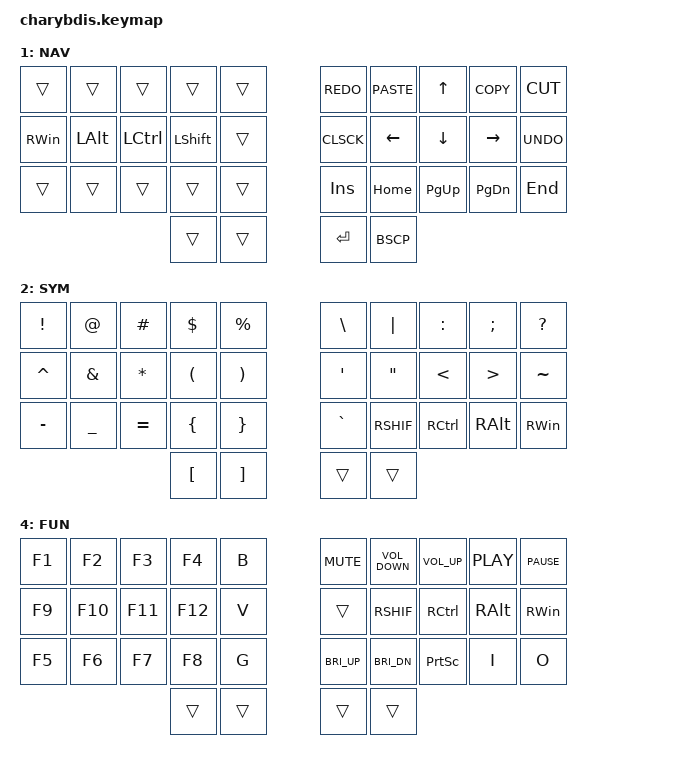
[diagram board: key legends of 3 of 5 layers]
#include <behaviors/mouse_keys.dtsi>
#include <behaviors.dtsi>
#include <dt-bindings/zmk/bt.h>
#include <dt-bindings/zmk/keys.h>
#include <dt-bindings/zmk/mouse.h>
#include <dt-bindings/zmk/outputs.h>

#define U_TAPPING_TERM 200

/ {
    chosen { zmk,matrix_transform = &default_transform; };
};

/ {
    combos {
        compatible = "zmk,combos";

        Combo_Num {
            bindings = <&mo NUM>;
            key-positions = <32 33>;  # Las posiciones de las dos teclas que quieres usar
        };
        Combo_Nav {
            bindings = <&mo NAV>;
            key-positions = <31 34>;  # Las posiciones de las dos teclas que quieres usar
        };
    };

    behaviors {
        u_mt: u_mt {
            compatible = "zmk,behavior-hold-tap";
            label = "u_mt";
            #binding-cells = <2>;
            tapping_term_ms = <U_TAPPING_TERM>;
            flavor = "tap-preferred";
            bindings = <&kp>, <&kp>;
        };

        u_lt: u_lt {
            compatible = "zmk,behavior-hold-tap";
            label = "u_lt";
            #binding-cells = <2>;
            tapping_term_ms = <U_TAPPING_TERM>;
            flavor = "tap-preferred";
            bindings = <&mo>, <&kp>;
        };

        Shift_Enter: Shift_Enter {
            compatible = "zmk,behavior-hold-tap";
            label = "SHIFT_ENTER";
            bindings = <&kp>, <&kp>;

            #binding-cells = <2>;
            hold-trigger-key-positions = <40>;
            tapping-term-ms = <100>;
        };
    };

    keymap {
        compatible = "zmk,keymap";
        BASE {
            bindings = <
        &kp Q   &kp W   &kp F   &kp P   &kp B                       &kp J  &kp L &kp U   &kp Y   &kp APOS
        &kp A   &kp R   &kp S   &kp T   &kp G                       &kp M  &kp N &kp E   &kp I   &kp O
        &kp Z   &kp X   &kp C   &kp D   &kp V                       &kp K  &kp H &kp COMMA   &kp DOT   &kp FSLH
                          &mo FUN &kp TAB  &kp SPACE                &mo SYM &kp RET  &kp BSCP
            >;
        };

        NAV {
            bindings = <
    &trans  &trans  &trans  &trans  &trans                      &kp C_REDO  &kp C_PASTE  &kp UP    &kp C_COPY  &kp C_CUT
    &kp RWIN  &kp LALT   &kp LCTRL   &kp LSHIFT  &trans         &kp CLSCK   &kp LEFT     &kp DOWN  &kp RIGHT   &kp C_UNDO
    &trans  &trans  &trans  &trans  &trans                      &kp INSERT  &kp HOME     &kp PG_UP &kp PG_DN   &kp END
                                &trans   &trans              &kp RET  &kp BSCP
            >;
        };
        SYM {
            bindings = <
    &kp EXCL  &kp AT   &kp HASH   &kp DLLR  &kp PRCNT        &kp BSLH   &kp PIPE &kp COLON  &kp SEMI   &kp QMARK 
    &kp CARET &kp AMPS &kp STAR   &kp LPAR  &kp RPAR         &kp APOS   &kp DQT  &kp LT  &kp GT   &kp TILDE
    &kp MINUS &kp UNDER &kp EQUAL &kp LBRC  &kp RBRC         &kp GRAVE  &kp RSHIF &kp RCTRL   &kp RALT   &kp RWIN
                                  &kp LBKT  &kp RBKT         &trans     &trans
            >;
        };

        NUM {
            bindings = <
        &kp 1   &kp 2   &kp 3   &kp 4   &kp 5             &trans  &trans   &trans  &trans
        &kp 6   &kp 7   &kp 8   &kp 9   &kp 0             &trans  &kp RSHIF &kp RCTRL   &kp RALT   &kp RWIN
        &kp 9   &trans  &trans  &trans  &trans            &trans  &trans  &trans  &trans
                                &trans  &trans            &trans  &trans
            >;
        };

        FUN {
            bindings = <

        &kp F1   &kp F2   &kp F3   &kp F4   &kp B                       &kp C_MUTE &kp C_VOL_DOWN &kp C_VOL_UP &kp C_PLAY &kp C_PAUSE
        &kp F9   &kp F10  &kp F11  &kp F12  &kp V                       &trans  &kp RSHIF &kp RCTRL   &kp RALT   &kp RWIN 
        &kp F5   &kp F6   &kp F7   &kp F8   &kp G                       &kp C_BRI_UP &kp C_BRI_DN &kp PSCRN   &kp I   &kp O
                                   &trans  &trans                      &trans  &trans
            >;
                };
    };
};
